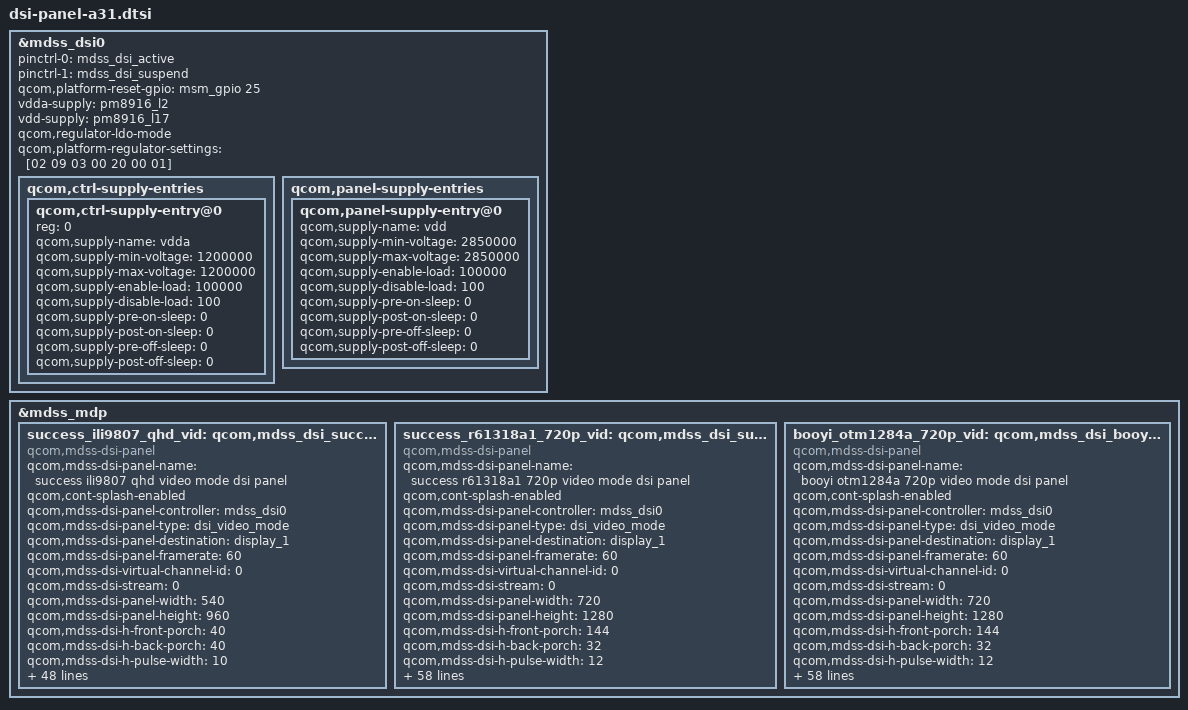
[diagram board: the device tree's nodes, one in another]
/* Copyright (c) 2013, The Linux Foundation. All rights reserved.
 *
 * This program is free software; you can redistribute it and/or modify
 * it under the terms of the GNU General Public License version 2 and
 * only version 2 as published by the Free Software Foundation.
 *
 * This program is distributed in the hope that it will be useful,
 * but WITHOUT ANY WARRANTY; without even the implied warranty of
 * MERCHANTABILITY or FITNESS FOR A PARTICULAR PURPOSE.  See the
 * GNU General Public License for more details.
 */

/*---------------------------------------------------------------------------
 * This file is autogenerated file using gcdb parser. Please do not edit it.
 * Update input XML file to add a new entry or update variable in this file
 * VERSION = "1.0"
 *---------------------------------------------------------------------------*/
/*
&pmx_mdss {
	qcom,num-grp-pins = <1>;
	qcom,pins = <&gp 25>;
};
*/
&mdss_dsi0 {
	pinctrl-names = "mdss_default", "mdss_sleep";
	pinctrl-0 = <&mdss_dsi_active>;
	pinctrl-1 = <&mdss_dsi_suspend>;

	qcom,platform-reset-gpio = <&msm_gpio 25 0>;
	vdda-supply = <&pm8916_l2>;
	vdd-supply = <&pm8916_l17>;
	qcom,regulator-ldo-mode;
	qcom,platform-regulator-settings = [02 09 03 00 20 00 01];

	qcom,ctrl-supply-entries {
		#address-cells = <1>;
		#size-cells = <0>;

		qcom,ctrl-supply-entry@0 {
			reg = <0>;
			qcom,supply-name = "vdda";
			qcom,supply-min-voltage = <1200000>;
			qcom,supply-max-voltage = <1200000>;
			qcom,supply-enable-load = <100000>;
			qcom,supply-disable-load = <100>;
			qcom,supply-pre-on-sleep = <0>;
			qcom,supply-post-on-sleep = <0>;
			qcom,supply-pre-off-sleep = <0>;
			qcom,supply-post-off-sleep = <0>;
		};
	};

	qcom,panel-supply-entries {
		#address-cells = <1>;
		#size-cells = <0>;

		qcom,panel-supply-entry@0 {
			qcom,supply-name = "vdd";
			qcom,supply-min-voltage = <2850000>;
			qcom,supply-max-voltage = <2850000>;
			qcom,supply-enable-load = <100000>;
			qcom,supply-disable-load = <100>;
			qcom,supply-pre-on-sleep = <0>;
			qcom,supply-post-on-sleep = <0>;
			qcom,supply-pre-off-sleep = <0>;
			qcom,supply-post-off-sleep = <0>;
		};
	};
};

&mdss_mdp {
	success_ili9807_qhd_vid:qcom,mdss_dsi_success_ili9807_qhd_video {
		compatible = "qcom,mdss-dsi-panel";
		qcom,mdss-dsi-panel-name = "success ili9807 qhd video mode dsi panel";
		qcom,cont-splash-enabled;
		qcom,mdss-dsi-panel-controller = <&mdss_dsi0>;
		qcom,mdss-dsi-panel-type = "dsi_video_mode";
		qcom,mdss-dsi-panel-destination = "display_1";
		qcom,mdss-dsi-panel-framerate = <60>;
		qcom,mdss-dsi-virtual-channel-id = <0>;
		qcom,mdss-dsi-stream = <0>;
		qcom,mdss-dsi-panel-width = <540>;
		qcom,mdss-dsi-panel-height = <960>;
		qcom,mdss-dsi-h-front-porch = <40>;
		qcom,mdss-dsi-h-back-porch = <40>;
		qcom,mdss-dsi-h-pulse-width = <10>;
		qcom,mdss-dsi-h-sync-skew = <0>;
		qcom,mdss-dsi-v-back-porch = <14>;
		qcom,mdss-dsi-v-front-porch = <20>;
		qcom,mdss-dsi-v-pulse-width = <6>;
		qcom,mdss-dsi-h-left-border = <0>;
		qcom,mdss-dsi-h-right-border = <0>;
		qcom,mdss-dsi-v-top-border = <0>;
		qcom,mdss-dsi-v-bottom-border = <0>;
		qcom,mdss-dsi-bpp = <24>;
		qcom,mdss-dsi-underflow-color = <0xff>;
		qcom,mdss-dsi-border-color = <0>;
		qcom,mdss-dsi-on-command = [
			39 01 00 00 00 00 06 FF FF 98 07 00 01
			15 01 00 00 00 00 02 31 00
			15 01 00 00 00 00 02 40 55
			15 01 00 00 00 00 02 41 33
			15 01 00 00 00 00 02 42 02
			15 01 00 00 00 00 02 43 09
			15 01 00 00 00 00 02 44 06
			15 01 00 00 00 00 02 46 DD
			15 01 00 00 00 00 02 47 BB
			15 01 00 00 00 00 02 50 78
			15 01 00 00 00 00 02 51 78
			15 01 00 00 00 00 02 52 00
			15 01 00 00 00 00 02 53 64
			15 01 00 00 00 00 02 60 02
			15 01 00 00 00 00 02 61 00
			15 01 00 00 00 00 02 62 08
			15 01 00 00 00 00 02 63 00
			15 01 00 00 00 00 02 64 88
			39 01 00 00 00 00 06 FF FF 98 07 00 01
			15 01 00 00 00 00 02 A0 00
			15 01 00 00 00 00 02 A1 06
			15 01 00 00 00 00 02 A2 0B
			15 01 00 00 00 00 02 A3 0C
			15 01 00 00 00 00 02 A4 05
			15 01 00 00 00 00 02 A5 0A
			15 01 00 00 00 00 02 A6 08
			15 01 00 00 00 00 02 A7 07
			15 01 00 00 00 00 02 A8 05
			15 01 00 00 00 00 02 A9 09
			15 01 00 00 00 00 02 AA 0E
			15 01 00 00 00 00 02 AB 08
			15 01 00 00 00 00 02 AC 0E
			15 01 00 00 00 00 02 AD 14
			15 01 00 00 00 00 02 AE 0D
			15 01 00 00 00 00 02 AF 00
			15 01 00 00 00 00 02 C0 00
			15 01 00 00 00 00 02 C1 06
			15 01 00 00 00 00 02 C2 0B
			15 01 00 00 00 00 02 C3 0C
			15 01 00 00 00 00 02 C4 05
			15 01 00 00 00 00 02 C5 0A
			15 01 00 00 00 00 02 C6 08
			15 01 00 00 00 00 02 C7 07
			15 01 00 00 00 00 02 C8 05
			15 01 00 00 00 00 02 C9 0A
			15 01 00 00 00 00 02 CA 0E
			15 01 00 00 00 00 02 CB 08
			15 01 00 00 00 00 02 CC 0E
			15 01 00 00 00 00 02 CD 14
			15 01 00 00 00 00 02 CE 0D
			15 01 00 00 00 00 02 CF 00
			39 01 00 00 00 00 06 FF FF 98 07 00 06
			15 01 00 00 00 00 02 00 21
			15 01 00 00 00 00 02 01 06
			15 01 00 00 00 00 02 02 00
			15 01 00 00 00 00 02 03 00
			15 01 00 00 00 00 02 04 16
			15 01 00 00 00 00 02 05 16
			15 01 00 00 00 00 02 06 80
			15 01 00 00 00 00 02 07 02
			15 01 00 00 00 00 02 08 05
			15 01 00 00 00 00 02 09 00
			15 01 00 00 00 00 02 0A 00
			15 01 00 00 00 00 02 0B 00
			15 01 00 00 00 00 02 0C 26
			15 01 00 00 00 00 02 0D 26
			15 01 00 00 00 00 02 0E 0F
			15 01 00 00 00 00 02 0F 00
			15 01 00 00 00 00 02 10 77
			15 01 00 00 00 00 02 11 F0
			15 01 00 00 00 00 02 12 00
			15 01 00 00 00 00 02 13 00
			15 01 00 00 00 00 02 14 00
			15 01 00 00 00 00 02 15 C0
			15 01 00 00 00 00 02 16 08
			15 01 00 00 00 00 02 17 00
			15 01 00 00 00 00 02 18 00
			15 01 00 00 00 00 02 19 00
			15 01 00 00 00 00 02 1A 00
			15 01 00 00 00 00 02 1B 00
			15 01 00 00 00 00 02 1C 00
			15 01 00 00 00 00 02 1D 00
			15 01 00 00 00 00 02 20 01
			15 01 00 00 00 00 02 21 23
			15 01 00 00 00 00 02 22 45
			15 01 00 00 00 00 02 23 67
			15 01 00 00 00 00 02 24 01
			15 01 00 00 00 00 02 25 23
			15 01 00 00 00 00 02 26 45
			15 01 00 00 00 00 02 27 67
			15 01 00 00 00 00 02 30 01
			15 01 00 00 00 00 02 31 22
			15 01 00 00 00 00 02 32 22
			15 01 00 00 00 00 02 33 11
			15 01 00 00 00 00 02 34 00
			15 01 00 00 00 00 02 35 86
			15 01 00 00 00 00 02 36 68
			15 01 00 00 00 00 02 37 22
			15 01 00 00 00 00 02 38 22
			15 01 00 00 00 00 02 39 DA
			15 01 00 00 00 00 02 3A BC
			15 01 00 00 00 00 02 3B CB
			15 01 00 00 00 00 02 3C AD
			15 01 00 00 00 00 02 3D 22
			15 01 00 00 00 00 02 3E 22
			15 01 00 00 00 00 02 3F 22
			15 01 00 00 00 00 02 40 22
			15 01 00 00 00 00 02 41 22
			15 01 00 00 00 00 02 42 22
			15 01 00 00 00 00 02 43 22
			39 01 00 00 00 00 06 FF FF 98 07 00 07
			15 01 00 00 00 00 02 02 77
			39 01 00 00 00 00 06 FF FF 98 07 00 00
			05 01 00 00 78 00 02 11 00];
		qcom,mdss-dsi-off-command = [05 01 00 00 32 00 02 28 00
								05 01 00 00 78 00 02 10 00];
		qcom,display-on-cmds = [05 01 00 00 C8 00 02 29 00];
		qcom,mdss-dsi-on-command-state = "dsi_lp_mode";
		qcom,mdss-dsi-off-command-state = "dsi_hs_mode";
		qcom,mdss-dsi-default-command-state = "dsi_hs_mode";
		qcom,mdss-dsi-h-sync-pulse = <1>;
		qcom,mdss-dsi-traffic-mode = "burst_mode";
		qcom,mdss-dsi-bllp-eof-power-mode;
		qcom,mdss-dsi-lane-map = "lane_map_3012";
		qcom,mdss-dsi-bllp-power-mode;
		qcom,mdss-dsi-lane-0-state;
		qcom,mdss-dsi-lane-1-state;
		qcom,mdss-dsi-panel-timings = [80 1D 13 00 42 46 18 20 20 03 04 00];
		qcom,mdss-dsi-t-clk-post = <0x04>;
		qcom,mdss-dsi-t-clk-pre = <0x1b>;
		qcom,mdss-dsi-bl-min-level = <1>;
		qcom,mdss-dsi-bl-max-level = <255>;
		qcom,mdss-dsi-dma-trigger = "trigger_sw";
		qcom,mdss-dsi-mdp-trigger = "none";
		qcom,mdss-dsi-bl-pmic-control-type = "bl_ctrl_pwm";
		qcom,mdss-dsi-bl-pmic-pwm-frequency = <40>;
		qcom,mdss-dsi-bl-pmic-bank-select = <0>;
		qcom,mdss-dsi-pwm-gpio = <&pm8916_mpps 4 0>;
		qcom,mdss-pan-physical-width-dimension = <62>;
		qcom,mdss-pan-physical-height-dimension = <110>;
		qcom,mdss-shrink-pwm = <8 113 255>;
		qcom,mdss-dsi-lp11-init;
		htc,mdss-camera-blk = <213>;
		htc,panel-id=<1>;
		htc,skip-frame;
	};

	success_r61318a1_720p_vid:qcom,mdss_dsi_success_r61318a1_720p_video {
		compatible = "qcom,mdss-dsi-panel";
		qcom,mdss-dsi-panel-name = "success r61318a1 720p video mode dsi panel";
		qcom,cont-splash-enabled;
		qcom,mdss-dsi-panel-controller = <&mdss_dsi0>;
		qcom,mdss-dsi-panel-type = "dsi_video_mode";
		qcom,mdss-dsi-panel-destination = "display_1";
		qcom,mdss-dsi-panel-framerate = <60>;
		qcom,mdss-dsi-virtual-channel-id = <0>;
		qcom,mdss-dsi-stream = <0>;
		qcom,mdss-dsi-panel-width = <720>;
		qcom,mdss-dsi-panel-height = <1280>;
		qcom,mdss-dsi-h-front-porch = <144>;
		qcom,mdss-dsi-h-back-porch = <32>;
		qcom,mdss-dsi-h-pulse-width = <12>;
		qcom,mdss-dsi-h-sync-skew = <0>;
		qcom,mdss-dsi-v-back-porch = <12>;
		qcom,mdss-dsi-v-front-porch = <16>;
		qcom,mdss-dsi-v-pulse-width = <2>;
		qcom,mdss-dsi-h-left-border = <0>;
		qcom,mdss-dsi-h-right-border = <0>;
		qcom,mdss-dsi-v-top-border = <0>;
		qcom,mdss-dsi-v-bottom-border = <0>;
		qcom,mdss-dsi-bpp = <24>;
		qcom,mdss-dsi-underflow-color = <0xff>;
		qcom,mdss-dsi-border-color = <0>;
		qcom,mdss-dsi-on-command = [
			29 01 00 00 00 00 02 B0 00 /* access protect off */
			29 01 00 00 00 00 02 B3 00 /* clock setting */
			29 01 00 00 00 00 02 B6 32 /* DSI setting */
			23 01 00 00 00 00 02 BB 01
			29 01 00 00 00 00 06 B7 90 1E 10 1E AB
			29 01 00 00 00 00 12 B8 32 40 43 49 55 62 71 82 94 A8 B9 CB DB E9 F5 FC FF
			29 01 00 00 00 00 07 BC 04 00 04 04 00 00
			29 01 00 00 00 00 0B BD 80 83 95 b7 80 a8 F0 18 3F 14
			29 01 00 00 00 00 16 BE 8A 0A 4A 37 A0 55 F8 0C 0C 20 10 3F 3F 19 D6 10 10 3F 3F 3F 3F
			29 01 00 00 00 00 07 C0 23 B2 10 10 02 7F /* display setting */
			29 01 00 00 00 00 08 C1 A0 70 60 60 01 01 F0 /* display h-timing setting */
			29 01 00 00 00 00 04 C4 BC B0 01 /* GIP interface mode */
			29 01 00 00 00 00 04 C5 07 00 37 /* display v-timing setting */
			29 01 00 00 00 00 02 C6 21 /* panel drive setting */
			29 01 00 00 00 00 1D C8 61 4E 42 AA 90 5A 6B AD B5 D6 5A 6B 85 51 CA 08 6B AD B5 D6 5A 6B AD 95 14 85 D2 31 /* GOUT pin assignment */
			29 01 00 00 00 00 1F CA 06 0A 0C 10 16 1C 20 20 20 1F 1C 15 0F 09 02 06 09 0C 10 16 1C 20 20 20 1F 1C 15 0F 08 02 /* gamma setting of common */
			29 01 00 00 00 00 04 D0 05 8B 42 /* power setting of VCI, VGH, and VGL */
			29 01 00 00 00 00 02 D1 03 /* power setting of VCL */
			29 01 00 00 00 00 03 D2 03 3F /* power setting of external booster */
			29 01 00 00 00 00 03 D3 11 33 /* power setting of internal circuit */
			29 01 00 00 00 00 02 E5 02 /* register write control */
			29 01 00 00 00 00 02 D4 6E /* VCOMDC setting */
			29 01 00 00 00 00 03 D5 32 32 /* VPL VL and VNL VL */
			29 01 00 00 00 00 02 D6 01 /* abnormal off sequence control */
			39 01 00 00 00 00 02 53 2C /* pwm out */
			05 01 00 00 78 00 02 11 00]; /* sleep out */
		qcom,mdss-dsi-off-command = [05 01 00 00 32 00 02 28 00
					05 01 00 00 78 00 02 10 00];
		qcom,display-on-cmds = [05 01 00 00 14 00 02 29 00];
		qcom,mdss-dsi-on-command-state = "dsi_lp_mode";
		qcom,mdss-dsi-off-command-state = "dsi_hs_mode";
		qcom,mdss-dsi-default-command-state = "dsi_hs_mode";
		qcom,mdss-dsi-h-sync-pulse = <1>;
		qcom,mdss-dsi-traffic-mode = "burst_mode";
		qcom,mdss-dsi-bllp-eof-power-mode;
		qcom,mdss-dsi-lane-map = "0";
		qcom,mdss-dsi-bllp-power-mode;
		qcom,mdss-dsi-lane-0-state;
		qcom,mdss-dsi-lane-1-state;
		qcom,mdss-dsi-lane-2-state;
		qcom,mdss-dsi-lane-3-state;
		qcom,mdss-dsi-panel-timings = [7a 1a 12 00 3e 42 16 1e 14 03 04 00];
		qcom,mdss-dsi-t-clk-post = <0x04>;
		qcom,mdss-dsi-t-clk-pre = <0x1b>;
		qcom,mdss-dsi-bl-min-level = <1>;
		qcom,mdss-dsi-bl-max-level = <255>;
		qcom,mdss-dsi-dma-trigger = "trigger_sw";
		qcom,mdss-dsi-mdp-trigger = "none";
		qcom,mdss-dsi-bl-pmic-control-type = "bl_ctrl_dcs";
		qcom,mdss-pan-physical-width-dimension = <62>;
		qcom,mdss-pan-physical-height-dimension = <110>;
		qcom,mdss-shrink-pwm = <8 113 255>;
		qcom,mdss-dsi-lp11-init;
		htc,mdss-camera-blk = <213>;
		htc,panel-id=<2>;
		htc,skip-frame;
		htc,cabc-off-cmds = [39 01 00 00 00 00 02 55 00];
		htc,cabc-ui-cmds = [39 01 00 00 00 00 02 55 02];
		htc,cabc-video-cmds = [39 01 00 00 00 00 02 55 03];
		htc,dimming-on-cmds = [39 01 00 00 00 00 02 53 2C];
		htc,dimming-off-cmds = [39 01 00 00 00 00 02 53 24];
		htc,dimming-switch-cmds = [39 01 00 00 00 00 02 53 2C
					39 01 00 00 00 00 02 53 24];
	};

	booyi_otm1284a_720p_vid:qcom,mdss_dsi_booyi_otm1284a_720p_video {
		compatible = "qcom,mdss-dsi-panel";
		qcom,mdss-dsi-panel-name = "booyi otm1284a 720p video mode dsi panel";
		qcom,cont-splash-enabled;
		qcom,mdss-dsi-panel-controller = <&mdss_dsi0>;
		qcom,mdss-dsi-panel-type = "dsi_video_mode";
		qcom,mdss-dsi-panel-destination = "display_1";
		qcom,mdss-dsi-panel-framerate = <60>;
		qcom,mdss-dsi-virtual-channel-id = <0>;
		qcom,mdss-dsi-stream = <0>;
		qcom,mdss-dsi-panel-width = <720>;
		qcom,mdss-dsi-panel-height = <1280>;
		qcom,mdss-dsi-h-front-porch = <144>;
		qcom,mdss-dsi-h-back-porch = <32>;
		qcom,mdss-dsi-h-pulse-width = <12>;
		qcom,mdss-dsi-h-sync-skew = <0>;
		qcom,mdss-dsi-v-back-porch = <22>;
		qcom,mdss-dsi-v-front-porch = <22>;
		qcom,mdss-dsi-v-pulse-width = <4>;
		qcom,mdss-dsi-h-left-border = <0>;
		qcom,mdss-dsi-h-right-border = <0>;
		qcom,mdss-dsi-v-top-border = <0>;
		qcom,mdss-dsi-v-bottom-border = <0>;
		qcom,mdss-dsi-bpp = <24>;
		qcom,mdss-dsi-underflow-color = <0xff>;
		qcom,mdss-dsi-border-color = <0>;
		qcom,mdss-dsi-on-command = [
			39 01 00 00 00 00 02 00 00
			39 01 00 00 00 00 04 ff 12 84 01 /* EXTC=1 */
			39 01 00 00 00 00 02 00 80 /* Orise mode enable */
			39 01 00 00 00 00 03 ff 12 84
			39 01 00 00 00 00 02 00 92 /* Orise mode enable */
			39 01 00 00 00 00 03 ff 30 02

			/* panel setting */
			39 01 00 00 00 00 02 00 80 /* TCON Setting */
			39 01 00 00 00 00 0a c0 00 64 00 10 10 00 64 10 10
			39 01 00 00 00 00 02 00 90 /* Panel Timing Setting */
			39 01 00 00 00 00 07 c0 00 5c 00 01 00 04
			39 01 00 00 00 00 02 00 b3 /* Interval Scan Frame: 0 frame, column inversion */
			39 01 00 00 00 00 03 c0 00 55
			39 01 00 00 00 00 02 00 81 /* frame rate:60Hz */
			39 01 00 00 00 00 02 c1 55

			/* power setting */
			39 01 00 00 00 00 02 00 a0 /* dcdc setting */
			39 01 00 00 00 00 0F c4 05 10 06 02 05 15 10 05 10 07 02 05 15 10
			39 01 00 00 00 00 02 00 b0 /* clamp voltage setting */
			39 01 00 00 00 00 03 c4 00 00
			39 01 00 00 00 00 02 00 91 /* VGH=15V, VGL=-10V, pump ratio:VGH=6x, VGL=-5x */
			39 01 00 00 00 00 03 c5 46 42
			39 01 00 00 00 00 02 00 00 /* GVDD=4.87V, NGVDD=-4.87V */
			39 01 00 00 00 00 03 d8 bc bc
			39 01 00 00 00 00 02 00 00 /* VCOMDC=-0.9 */
			39 01 00 00 00 00 02 d9 9A /* 7b */
			39 01 00 00 00 00 02 00 b3 /* VDD_18V=1.7V, LVDSVDD=1.6V */
			39 01 00 00 00 00 02 c5 44
			39 01 00 00 00 00 02 00 bb /* LVD voltage level setting */
			39 01 00 00 00 00 02 c5 8a
			39 01 00 00 00 00 02 00 82 /* chopper */
			39 01 00 00 00 00 02 C4 0a
			39 01 00 00 00 00 02 00 c6 /* debounce */
			39 01 00 00 00 00 02 B0 03
			39 01 00 00 00 00 02 00 c2 /* precharge disable */
			39 01 00 00 00 00 02 f5 40
			39 01 00 00 00 00 02 00 c3 /* sample hold gvdd */
			39 01 00 00 00 00 02 f5 85
			39 01 00 00 00 00 02 00 87 /* en op */
			39 01 00 00 00 00 02 c4 18

			/* control setting */
			39 01 00 00 00 00 02 00 00 /* ID1 */
			39 01 00 00 00 00 02 d0 40
			39 01 00 00 00 00 02 00 00 /* ID2, ID3 */
			39 01 00 00 00 00 03 d1 00 00

			/* panel timing state control */
			39 01 00 00 00 00 02 00 80 /* panel timing state control */
			39 01 00 00 00 00 0C cb 00 00 00 00 00 00 00 00 00 00 00
			39 01 00 00 00 00 02 00 90 /* panel timing state control */
			39 01 00 00 00 00 10 cb 00 00 00 00 00 00 00 00 00 00 00 00 00 00 00
			39 01 00 00 00 00 02 00 a0 /* panel timing state control */
			39 01 00 00 00 00 10 cb 00 00 00 00 00 00 00 00 00 00 00 00 00 00 00
			39 01 00 00 00 00 02 00 b0 /* panel timing state control */
			39 01 00 00 00 00 10 cb 00 00 00 00 00 00 00 00 00 00 00 00 00 00 00
			39 01 00 00 00 00 02 00 c0 /* panel timing state control */
			39 01 00 00 00 00 10 cb 05 05 05 05 05 00 00 00 00 00 00 00 00 00 00
			39 01 00 00 00 00 02 00 d0 /* panel timing state control */
			39 01 00 00 00 00 10 cb ff ff ff 00 05 05 05 05 05 05 05 05 00 00 00
			39 01 00 00 00 00 02 00 e0 /* panel timing state control */
			39 01 00 00 00 00 0F cb 00 00 00 00 00 00 00 ff ff ff 00 05 05 05
			39 01 00 00 00 00 02 00 f0 /* panel timing state control */
			39 01 00 00 00 00 0C cb ff ff ff ff ff ff ff ff ff ff ff

			/* panel pad mapping control */
			39 01 00 00 00 00 02 00 80 /* panel pad mapping control */
			39 01 00 00 00 00 10 cc 02 0a 0c 0e 10 00 00 00 00 00 00 00 00 00 00
			39 01 00 00 00 00 02 00 90 /* panel pad mapping control */
			39 01 00 00 00 00 10 cc 00 00 00 00 2e 2d 06 01 09 0b 0d 0f 00 00 00
			39 01 00 00 00 00 02 00 a0 /* panel pad mapping control */
			39 01 00 00 00 00 0F cc 00 00 00 00 00 00 00 00 00 00 00 2e 2d 05
			39 01 00 00 00 00 02 00 b0 /* panel pad mapping control */
			39 01 00 00 00 00 10 cc 05 0f 0d 0b 09 00 00 00 00 00 00 00 00 00 00
			39 01 00 00 00 00 02 00 c0 /* panel pad mapping control */
			39 01 00 00 00 00 10 cc 00 00 00 00 2d 2e 01 06 10 0e 0c 0a 00 00 00
			39 01 00 00 00 00 02 00 d0 /* panel pad mapping control */
			39 01 00 00 00 00 0F cc 00 00 00 00 00 00 00 00 00 00 00 2d 2e 02

			/* panel timing setting */
			39 01 00 00 00 00 02 00 80 /* panel VST setting */
			39 01 00 00 00 00 0D ce 87 03 10 86 03 10 00 00 00 00 00 00
			39 01 00 00 00 00 02 00 90 /* panel VEND setting */
			39 01 00 00 00 00 0F ce 35 01 10 35 02 10 00 00 00 00 00 00 00 00
			39 01 00 00 00 00 02 00 a0 /* panel CLKA1/2 setting */
			39 01 00 00 00 00 0F ce 38 03 04 f8 00 10 00 38 02 04 f9 00 10 00
			39 01 00 00 00 00 02 00 b0 /* panel CLKA3/4 setting */
			39 01 00 00 00 00 0F ce 38 01 04 fa 00 10 00 38 00 04 fb 00 10 00
			39 01 00 00 00 00 02 00 c0 /* panel CLKb1/2 setting */
			39 01 00 00 00 00 0F ce 30 00 04 fc 00 10 00 30 01 04 fd 00 10 00
			39 01 00 00 00 00 02 00 d0 /* panel CLKb3/4 setting */
			39 01 00 00 00 00 0F ce 30 02 04 fe 00 10 00 30 03 04 ff 00 10 00
			39 01 00 00 00 00 02 00 80 /* panel CLKc1/2 setting */
			39 01 00 00 00 00 0F cf 00 00 00 00 00 00 00 00 00 00 00 00 00 00
			39 01 00 00 00 00 02 00 90 /* panel CLKc3/4 setting */
			39 01 00 00 00 00 0F cf 00 00 00 00 00 00 00 00 00 00 00 00 00 00
			39 01 00 00 00 00 02 00 a0 /* panel CLKd1/2 setting */
			39 01 00 00 00 00 0F cf 00 00 00 00 00 00 00 00 00 00 00 00 00 00
			39 01 00 00 00 00 02 00 b0 /* panel CLKd3/4 setting */
			39 01 00 00 00 00 0F cf 00 00 00 00 00 00 00 00 00 00 00 00 00 00
			39 01 00 00 00 00 02 00 c0 /* panel ECLK setting */
			39 01 00 00 00 00 0C cf 01 01 20 20 00 00 01 81 00 03 08 /* gate pre. ena. */
			39 01 00 00 00 00 02 00 b5 /* TCON_GOA_OUT setting */
			39 01 00 00 00 00 07 c5 3f ff ff 3f ff ff

			/* for Power IC */
			39 01 00 00 00 00 02 00 90 /* Mode-3 */
			39 01 00 00 00 00 05 f5 02 11 02 15
			39 01 00 00 00 00 02 00 90 /* 2xVPNL */
			39 01 00 00 00 00 02 c5 50
			39 01 00 00 00 00 02 00 94 /* Freq. */
			39 01 00 00 00 00 02 c5 66

			/* VGLO1/O2 disable */
			39 01 00 00 00 00 02 00 b2 /* VGLO1 */
			39 01 00 00 00 00 03 f5 00 00
			39 01 00 00 00 00 02 00 b4 /* VGLO1_S */
			39 01 00 00 00 00 03 f5 00 00
			39 01 00 00 00 00 02 00 b6 /* VGLO2 */
			39 01 00 00 00 00 03 f5 00 00
			39 01 00 00 00 00 02 00 b8 /* VGLO2_S */
			39 01 00 00 00 00 03 f5 00 00
			39 01 00 00 00 00 02 00 94 /* VCL pump dis */
			39 01 00 00 00 00 03 f5 00 00
			39 01 00 00 00 00 02 00 d2 /* VCL reg. en */
			39 01 00 00 00 00 03 f5 06 15
			39 01 00 00 00 00 02 00 b4 /* VGLO1/2 Pull low setting */
			39 01 00 00 00 00 02 c5 cc /* d[7] vglo1 d[6] vglo2 => 0: pull vss, 1: pull vgl */

			/* Gamma */
			39 01 00 00 00 00 02 00 00
			39 01 00 00 00 00 15 E1 00 09 11 19 27 32 35 64 5C 7C 80 65 73 48 45 33 24 16 0A 00
			39 01 00 00 00 00 02 00 00
			39 01 00 00 00 00 15 E2 00 09 11 19 27 32 35 64 5C 7C 80 65 73 48 45 33 24 16 0A 00

			23 01 00 00 00 00 02 00 00
			29 01 00 00 00 00 22 ec 40 34 34 44 43 34 44 43 34 44 43 34 44 43 34 44 43 34 44 43 34 44 43 43 34 44 43 34 44 43 34 44 03
			23 01 00 00 00 00 02 00 00
			23 01 00 00 00 00 02 00 00
			29 01 00 00 00 00 22 ed 40 43 43 34 34 34 44 43 43 34 34 34 44 43 43 34 34 34 44 43 43 34 34 34 44 43 43 43 34 34 44 43 03
			23 01 00 00 00 00 02 00 00
			23 01 00 00 00 00 02 00 00
			29 01 00 00 00 00 22 ee 40 43 44 44 44 44 44 44 44 44 44 44 44 44 44 44 44 44 44 44 44 44 44 44 44 44 44 44 44 44 44 44 05
			23 01 00 00 00 00 02 00 00

			/* ce */
			23 01 00 00 00 00 02 00 a0
			29 01 00 00 00 00 0D d6 09 65 75 5c 15 9f 29 b5 01 fd 7d a9
			23 01 00 00 00 00 02 00 b0
			29 01 00 00 00 00 0D d6 7d 85 01 1a 71 fd 75 4d 0d 36 31 fd
			23 01 00 00 00 00 02 00 c0
			29 01 00 00 00 00 0D d6 41 11 3a 55 11 9a a9 11 91 22 11 3c
			23 01 00 00 00 00 02 00 d0
			29 01 00 00 00 00 07 d6 a9 11 a9 a9 11 a9
			23 01 00 00 00 00 02 00 e0
			29 01 00 00 00 00 0D d6 10 11 18 07 11 0f 05 11 2f 10 11 15
			23 01 00 00 00 00 02 00 f0
			29 01 00 00 00 00 07 d6 15 11 11 05 11 40
			23 01 00 00 00 00 02 00 00
			23 01 00 00 00 00 02 81 81

			39 01 00 00 00 00 02 00 00 /* Orise mode disable */
			39 01 00 00 00 00 04 ff ff ff ff
			39 01 00 00 00 00 02 53 2C /* pwm enable */
			05 01 00 00 7F 00 02 11 00]; /* sleep out */
		qcom,mdss-dsi-off-command = [05 01 00 00 32 00 02 28 00
					05 01 00 00 78 00 02 10 00];
		qcom,display-on-cmds = [05 01 00 00 14 00 02 29 00];
		qcom,mdss-dsi-on-command-state = "dsi_lp_mode";
		qcom,mdss-dsi-off-command-state = "dsi_hs_mode";
		qcom,mdss-dsi-default-command-state = "dsi_hs_mode";
		qcom,mdss-dsi-h-sync-pulse = <1>;
		qcom,mdss-dsi-traffic-mode = "burst_mode";
		qcom,mdss-dsi-bllp-eof-power-mode;
		qcom,mdss-dsi-lane-map = <0>;
		qcom,mdss-dsi-bllp-power-mode;
		qcom,mdss-dsi-lane-0-state;
		qcom,mdss-dsi-lane-1-state;
		qcom,mdss-dsi-lane-2-state;
		qcom,mdss-dsi-lane-3-state;
		qcom,mdss-dsi-panel-timings = [92 1C 12 00 40 42 16 1E 14 03 04 00];
		qcom,mdss-dsi-t-clk-post = <0x20>;
		qcom,mdss-dsi-t-clk-pre = <0x2d>;
		qcom,mdss-dsi-bl-min-level = <1>;
		qcom,mdss-dsi-bl-max-level = <255>;
		qcom,mdss-dsi-dma-trigger = "trigger_sw";
		qcom,mdss-dsi-mdp-trigger = "none";
		qcom,mdss-dsi-bl-pmic-control-type = "bl_ctrl_dcs";
		qcom,mdss-pan-physical-width-dimension = <62>;
		qcom,mdss-pan-physical-height-dimension = <110>;
		qcom,mdss-shrink-pwm = <8 113 255>;
		qcom,mdss-dsi-lp11-init;
		htc,mdss-camera-blk = <213>;
		htc,panel-id=<3>;
		htc,skip-frame;
		htc,cabc-off-cmds = [39 01 00 00 00 00 02 55 00];
		htc,cabc-ui-cmds = [39 01 00 00 00 00 02 55 02];
		htc,cabc-video-cmds = [39 01 00 00 00 00 02 55 03];
		htc,dimming-on-cmds = [39 01 00 00 00 00 02 53 2C];
		htc,dimming-off-cmds = [39 01 00 00 00 00 02 53 24];
		htc,dimming-switch-cmds = [39 01 00 00 00 00 02 53 2C
					39 01 00 00 00 00 02 53 24];
	};
};
